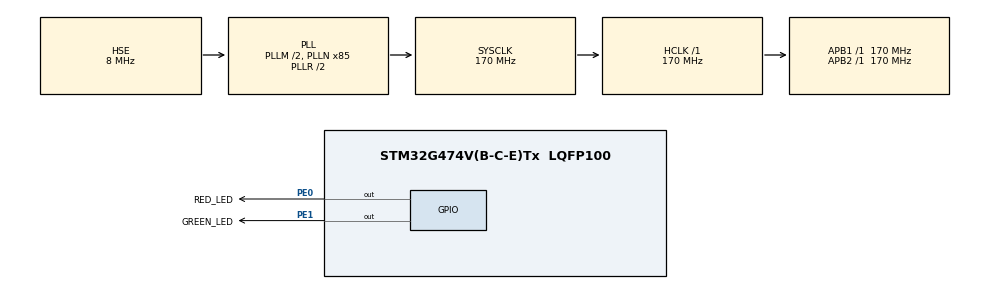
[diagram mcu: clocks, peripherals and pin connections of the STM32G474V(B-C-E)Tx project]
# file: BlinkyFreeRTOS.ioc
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FREERTOS.Tasks01=FlashRedLedTask,24,128,StartFlashRedLedTask,Default,NULL,Dynamic,NULL,NULL;FlashGreenLedTask,8,128,StartFlashGreenLedTask,Default,NULL,Dynamic,NULL,NULL
FREERTOS.configMAX_TASK_NAME_LEN=32
FREERTOS.configUSE_NEWLIB_REENTRANT=1
Mcu.Family=STM32G4
Mcu.Name=STM32G474V(B-C-E)Tx
Mcu.Package=LQFP100
NVIC.PriorityGroup=NVIC_PRIORITYGROUP_4
NVIC.TIM6_DAC_IRQn=true\:15\:0\:false\:false\:true\:false\:false\:true\:true
NVIC.TimeBase=TIM6_DAC_IRQn
NVIC.TimeBaseIP=TIM6
PE0.GPIO_Label=RED_LED
PE0.Signal=GPIO_Output
PE1.GPIO_Label=GREEN_LED
PE1.Signal=GPIO_Output
PF0-OSC_IN.Mode=HSE-External-Oscillator
PF0-OSC_IN.Signal=RCC_OSC_IN
PF1-OSC_OUT.Mode=HSE-External-Oscillator
PF1-OSC_OUT.Signal=RCC_OSC_OUT
ProjectManager.HeapSize=0x200
ProjectManager.StackSize=0x400
ProjectManager.TargetToolchain=STM32CubeIDE
RCC.ADC12Freq_Value=170000000
RCC.ADC345Freq_Value=170000000
RCC.AHBFreq_Value=170000000
RCC.APB1Freq_Value=170000000
RCC.APB1TimFreq_Value=170000000
RCC.APB2Freq_Value=170000000
RCC.APB2TimFreq_Value=170000000
RCC.CortexFreq_Value=170000000
RCC.EXTERNAL_CLOCK_VALUE=12288000
RCC.HCLKFreq_Value=170000000
RCC.HSE_VALUE=8000000
RCC.HSI48_VALUE=48000000
RCC.HSI_VALUE=16000000
RCC.LSE_VALUE=32768
RCC.PLLM=RCC_PLLM_DIV2
RCC.PLLN=85
RCC.PLLSourceVirtual=RCC_PLLSOURCE_HSE
RCC.SYSCLKFreq_VALUE=170000000
RCC.SYSCLKSource=RCC_SYSCLKSOURCE_PLLCLK
RCC.USBFreq_Value=170000000
RCC.VCOOutputFreq_Value=340000000
VP_FREERTOS_VS_CMSIS_V2.Mode=CMSIS_V2
VP_SYS_VS_DBSignals.Mode=DisableDeadBatterySignals
VP_SYS_VS_tim6.Mode=TIM6
board=custom

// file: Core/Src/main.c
/* USER CODE BEGIN Header */
/**
 ******************************************************************************
 * @file           : main.c
 * @brief          : Main program body
 ******************************************************************************
 * @attention
 *
 * Copyright (c) 2024 STMicroelectronics.
 * All rights reserved.
 *
 * This software is licensed under terms that can be found in the LICENSE file
 * in the root directory of this software component.
 * If no LICENSE file comes with this software, it is provided AS-IS.
 *
 ******************************************************************************
 */
/* USER CODE END Header */
#include "main.h"
#include "cmsis_os.h"
#include "gpio.h"

void SystemClock_Config(void);
void MX_FREERTOS_Init(void);

int main(void)
{

  /* MCU Configuration--------------------------------------------------------*/

  /* Reset of all peripherals, Initializes the Flash interface and the Systick. */
  HAL_Init();

  /* Configure the system clock */
  SystemClock_Config();

  /* Initialize all configured peripherals */
  MX_GPIO_Init();

  /* Init scheduler */
  osKernelInitialize();

  /* Call init function for freertos objects (in freertos.c) */
  MX_FREERTOS_Init();

  /* Start scheduler */
  osKernelStart();

  /* We should never get here as control is now taken by the scheduler */
  /* Infinite loop */
	while (1)
	{

	}
}

void SystemClock_Config(void)
{
  RCC_OscInitTypeDef RCC_OscInitStruct = {0};
  RCC_ClkInitTypeDef RCC_ClkInitStruct = {0};

  /** Configure the main internal regulator output voltage
  */
  HAL_PWREx_ControlVoltageScaling(PWR_REGULATOR_VOLTAGE_SCALE1_BOOST);

  /** Initializes the RCC Oscillators according to the specified parameters
  * in the RCC_OscInitTypeDef structure.
  */
  RCC_OscInitStruct.OscillatorType = RCC_OSCILLATORTYPE_HSE;
  RCC_OscInitStruct.HSEState = RCC_HSE_ON;
  RCC_OscInitStruct.PLL.PLLState = RCC_PLL_ON;
  RCC_OscInitStruct.PLL.PLLSource = RCC_PLLSOURCE_HSE;
  RCC_OscInitStruct.PLL.PLLM = RCC_PLLM_DIV2;
  RCC_OscInitStruct.PLL.PLLN = 85;
  RCC_OscInitStruct.PLL.PLLP = RCC_PLLP_DIV2;
  RCC_OscInitStruct.PLL.PLLQ = RCC_PLLQ_DIV2;
  RCC_OscInitStruct.PLL.PLLR = RCC_PLLR_DIV2;
  if (HAL_RCC_OscConfig(&RCC_OscInitStruct) != HAL_OK)
  {
    Error_Handler();
  }

  /** Initializes the CPU, AHB and APB buses clocks
  */
  RCC_ClkInitStruct.ClockType = RCC_CLOCKTYPE_HCLK|RCC_CLOCKTYPE_SYSCLK
                              |RCC_CLOCKTYPE_PCLK1|RCC_CLOCKTYPE_PCLK2;
  RCC_ClkInitStruct.SYSCLKSource = RCC_SYSCLKSOURCE_PLLCLK;
  RCC_ClkInitStruct.AHBCLKDivider = RCC_SYSCLK_DIV1;
  RCC_ClkInitStruct.APB1CLKDivider = RCC_HCLK_DIV1;
  RCC_ClkInitStruct.APB2CLKDivider = RCC_HCLK_DIV1;

  if (HAL_RCC_ClockConfig(&RCC_ClkInitStruct, FLASH_LATENCY_4) != HAL_OK)
  {
    Error_Handler();
  }
}

void HAL_TIM_PeriodElapsedCallback(TIM_HandleTypeDef *htim)
{
  if (htim->Instance == TIM6) {
    HAL_IncTick();
  }
}

void Error_Handler(void)
{
	__disable_irq();
	while (1)
	{
	}
}

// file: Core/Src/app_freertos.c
/* USER CODE BEGIN Header */
/**
 ******************************************************************************
 * File Name          : app_freertos.c
 * Description        : Code for freertos applications
 ******************************************************************************
 * @attention
 *
 * Copyright (c) 2024 STMicroelectronics.
 * All rights reserved.
 *
 * This software is licensed under terms that can be found in the LICENSE file
 * in the root directory of this software component.
 * If no LICENSE file comes with this software, it is provided AS-IS.
 *
 ******************************************************************************
 */
/* USER CODE END Header */

#include "FreeRTOS.h"
#include "task.h"
#include "main.h"
#include "cmsis_os.h"

/* Definitions for FlashRedLedTask */
osThreadId_t FlashRedLedTaskHandle;
const osThreadAttr_t FlashRedLedTask_attributes =
{ .name = "FlashRedLedTask", .priority = (osPriority_t) osPriorityNormal,
		.stack_size = 128 * 4 };
/* Definitions for FlashGreenLedTask */
osThreadId_t FlashGreenLedTaskHandle;
const osThreadAttr_t FlashGreenLedTask_attributes =
{ .name = "FlashGreenLedTask", .priority = (osPriority_t) osPriorityLow,
		.stack_size = 128 * 4 };

void StartFlashRedLedTask(void *argument);
void StartFlashGreenLedTask(void *argument);

void MX_FREERTOS_Init(void); /* (MISRA C 2004 rule 8.1) */

void MX_FREERTOS_Init(void)
{

	/* Create the thread(s) */
	/* creation of FlashRedLedTask */
	FlashRedLedTaskHandle = osThreadNew(StartFlashRedLedTask, NULL,
			&FlashRedLedTask_attributes);

	/* creation of FlashGreenLedTask */
	FlashGreenLedTaskHandle = osThreadNew(StartFlashGreenLedTask, NULL,
			&FlashGreenLedTask_attributes);

}

void StartFlashRedLedTask(void *argument)
{
	/* USER CODE BEGIN StartFlashRedLedTask */
	/* Infinite loop */
	for (;;)
	{
		HAL_GPIO_TogglePin(RED_LED_GPIO_Port, RED_LED_Pin);

		osDelay(500);
	}
	/* USER CODE END StartFlashRedLedTask */
}

void StartFlashGreenLedTask(void *argument)
{
	/* USER CODE BEGIN StartFlashGreenLedTask */
	/* Infinite loop */
	for (;;)
	{
		HAL_GPIO_TogglePin(GREEN_LED_GPIO_Port, GREEN_LED_Pin);

		osDelay(500);
	}
	/* USER CODE END StartFlashGreenLedTask */
}
